# MCXC444 register map
Vendor: NXP Semiconductors; Series: MCX; File version: 1.6
CPU: CM0PLUS r0p0, little endian, no MPU, no FPU, VTOR, 2 interrupt priority bits
Registers are 32-bit, read-write, reset 0x0 unless marked. A register's access mark holds for its fields unless they carry their own. Offsets are from the block's base; [hi:lo] are bit positions; 'fields as' and 'values as' point back to an identical list.

## I2S0 — Inter-IC Sound / Synchronous Audio Interface
Base 0x4002F000; register names take the prefix I2S0_
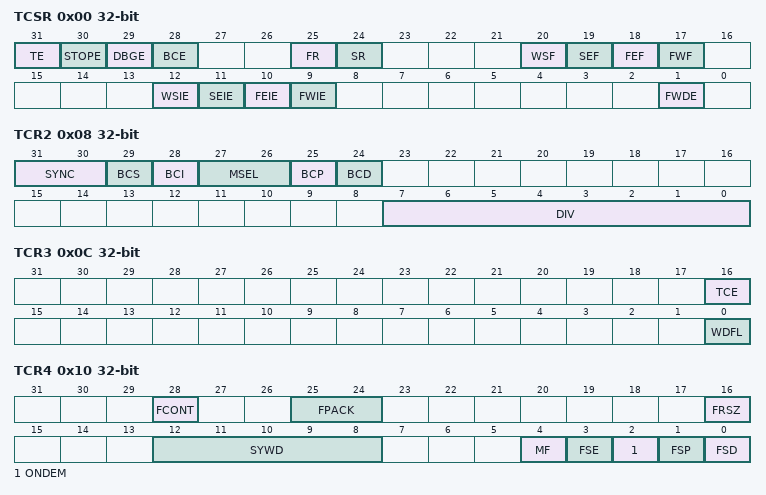
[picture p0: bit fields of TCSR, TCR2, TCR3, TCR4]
0x00 TCSR — SAI Transmit Control Register
  [31] TE — Transmitter Enable
    0=b0 (Transmitter is disabled.); 1=b1 (Transmitter is enabled, or transmitter has been disabled and has not yet reached end of frame.)
  [30] STOPE — Stop Enable
    0=b0 (Transmitter disabled in Stop mode.); 1=b1 (Transmitter enabled in Stop mode.)
  [29] DBGE — Debug Enable
    0=b0 (Transmitter is disabled in Debug mode, after completing the current frame.); 1=b1 (Transmitter is enabled in Debug mode.)
  [28] BCE — Bit Clock Enable
    0=b0 (Transmit bit clock is disabled.); 1=b1 (Transmit bit clock is enabled.)
  [25] FR — FIFO Reset
    0=b0 (No effect.); 1=b1 (FIFO reset.)
  [24] SR — Software Reset
    0=b0 (No effect.); 1=b1 (Software reset.)
  [20] WSF — Word Start Flag
    0=b0 (Start of word not detected.); 1=b1 (Start of word detected.)
  [19] SEF — Sync Error Flag
    0=b0 (Sync error not detected.); 1=b1 (Frame sync error detected.)
  [18] FEF — FIFO Error Flag
    0=b0 (Transmit underrun not detected.); 1=b1 (Transmit underrun detected.)
  [17] FWF ro — FIFO Warning Flag
    0=b0 (No enabled transmit FIFO is empty.); 1=b1 (Enabled transmit FIFO is empty.)
  [12] WSIE — Word Start Interrupt Enable
    0=b0 (Disables interrupt.); 1=b1 (Enables interrupt.)
  [11] SEIE — Sync Error Interrupt Enable
    0=b0 (Disables interrupt.); 1=b1 (Enables interrupt.)
  [10] FEIE — FIFO Error Interrupt Enable
    0=b0 (Disables the interrupt.); 1=b1 (Enables the interrupt.)
  [9] FWIE — FIFO Warning Interrupt Enable
    values as FEIE
  [1] FWDE — FIFO Warning DMA Enable
    0=b0 (Disables the DMA request.); 1=b1 (Enables the DMA request.)
0x08 TCR2 — SAI Transmit Configuration 2 Register
  [31:30] SYNC — Synchronous Mode
    0=b00 (Asynchronous mode.); 1=b01 (Synchronous with receiver.); 2=b10 (Synchronous with another SAI transmitter.); 3=b11 (Synchronous with another SAI receiver.)
  [29] BCS — Bit Clock Swap
    0=b0 (Use the normal bit clock source.); 1=b1 (Swap the bit clock source.)
  [28] BCI — Bit Clock Input
    0=b0 (No effect.); 1=b1 (Internal logic is clocked as if bit clock was externally generated.)
  [27:26] MSEL — MCLK Select
    0=b00 (Bus Clock selected.); 1=b01 (Master Clock (MCLK) 1 option selected.); 2=b10 (Master Clock (MCLK) 2 option selected.); 3=b11 (Master Clock (MCLK) 3 option selected.)
  [25] BCP — Bit Clock Polarity
    0=b0 (Bit clock is active high with drive outputs on rising edge and sample inputs on falling edge.); 1=b1 (Bit clock is active low with drive outputs on falling edge and sample inputs on rising edge.)
  [24] BCD — Bit Clock Direction
    0=b0 (Bit clock is generated externally in Slave mode.); 1=b1 (Bit clock is generated internally in Master mode.)
  [7:0] DIV — Bit Clock Divide
0x0C TCR3 — SAI Transmit Configuration 3 Register
  [16] TCE — Transmit Channel Enable
    0=b0 (Transmit data channel N is disabled.); 1=b1 (Transmit data channel N is enabled.)
  [0] WDFL — Word Flag Configuration
0x10 TCR4 — SAI Transmit Configuration 4 Register
  [28] FCONT — FIFO Continue on Error
    0=b0 (On FIFO error, the SAI will continue from the start of the next frame after the FIFO error flag has been cleared.); 1=b1 (On FIFO error, the SAI will continue from the same word that caused the FIFO error to set after the FIFO warning flag has been cleared.)
  [25:24] FPACK — FIFO Packing Mode
    0=b00 (FIFO packing is disabled); 2=b10 (8-bit FIFO packing is enabled); 3=b11 (16-bit FIFO packing is enabled)
  [16] FRSZ — Frame size
  [12:8] SYWD — Sync Width
  [4] MF — MSB First
    0=b0 (LSB is transmitted first.); 1=b1 (MSB is transmitted first.)
  [3] FSE — Frame Sync Early
    0=b0 (Frame sync asserts with the first bit of the frame.); 1=b1 (Frame sync asserts one bit before the first bit of the frame.)
  [2] ONDEM — On Demand Mode
    0=b0 (Internal frame sync is generated continuously.); 1=b1 (Internal frame sync is generated when the FIFO warning flag is clear.)
  [1] FSP — Frame Sync Polarity
    0=b0 (Frame sync is active high.); 1=b1 (Frame sync is active low.)
  [0] FSD — Frame Sync Direction
    0=b0 (Frame sync is generated externally in Slave mode.); 1=b1 (Frame sync is generated internally in Master mode.)
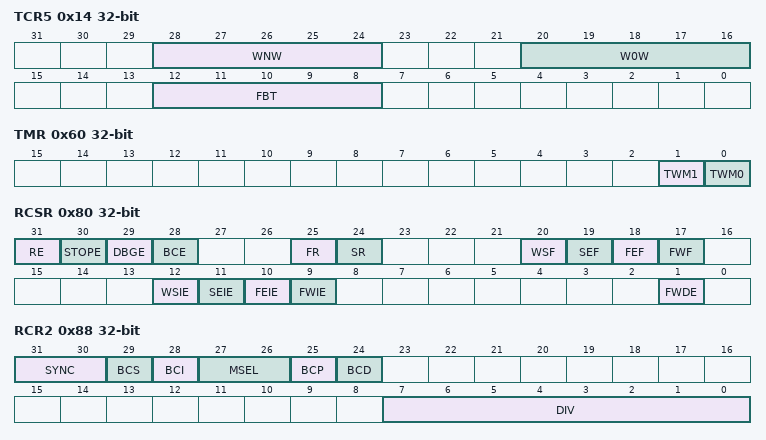
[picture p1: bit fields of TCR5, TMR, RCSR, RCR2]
0x14 TCR5 — SAI Transmit Configuration 5 Register
  [28:24] WNW — Word N Width
  [20:16] W0W — Word 0 Width
  [12:8] FBT — First Bit Shifted
0x20 TDR — SAI Transmit Data Register
  [31:0] TDR — Transmit Data Register
0x60 TMR — SAI Transmit Mask Register
  [1] TWM1 — Transmit Word Mask
    0=b00 (Word N is enabled.); 1=b01 (Word N is masked. The transmit data pins are tri-stated when masked.)
  [0] TWM0 — Transmit Word Mask
    values as TWM1
0x80 RCSR — SAI Receive Control Register
  [31] RE — Receiver Enable
    0=b0 (Receiver is disabled.); 1=b1 (Receiver is enabled, or receiver has been disabled and has not yet reached end of frame.)
  [30] STOPE — Stop Enable
    0=b0 (Receiver disabled in Stop mode.); 1=b1 (Receiver enabled in Stop mode.)
  [29] DBGE — Debug Enable
    0=b0 (Receiver is disabled in Debug mode, after completing the current frame.); 1=b1 (Receiver is enabled in Debug mode.)
  [28] BCE — Bit Clock Enable
    0=b0 (Receive bit clock is disabled.); 1=b1 (Receive bit clock is enabled.)
  [25] FR — FIFO Reset
    0=b0 (No effect.); 1=b1 (FIFO reset.)
  [24] SR — Software Reset
    0=b0 (No effect.); 1=b1 (Software reset.)
  [20] WSF — Word Start Flag
    values as TCSR.WSF
  [19] SEF — Sync Error Flag
    values as TCSR.SEF
  [18] FEF — FIFO Error Flag
    0=b0 (Receive overflow not detected.); 1=b1 (Receive overflow detected.)
  [17] FWF ro — FIFO Warning Flag
    0=b0 (No enabled receive FIFO is full.); 1=b1 (Enabled receive FIFO is full.)
  [12] WSIE — Word Start Interrupt Enable
    0=b0 (Disables interrupt.); 1=b1 (Enables interrupt.)
  [11] SEIE — Sync Error Interrupt Enable
    0=b0 (Disables interrupt.); 1=b1 (Enables interrupt.)
  [10] FEIE — FIFO Error Interrupt Enable
    values as TCSR.FEIE
  [9] FWIE — FIFO Warning Interrupt Enable
    values as TCSR.FEIE
  [1] FWDE — FIFO Warning DMA Enable
    values as TCSR.FWDE
0x88 RCR2 — SAI Receive Configuration 2 Register
  [31:30] SYNC — Synchronous Mode
    0=b00 (Asynchronous mode.); 1=b01 (Synchronous with transmitter.); 2=b10 (Synchronous with another SAI receiver.); 3=b11 (Synchronous with another SAI transmitter.)
  [29] BCS — Bit Clock Swap
    values as TCR2.BCS
  [28] BCI — Bit Clock Input
    values as TCR2.BCI
  [27:26] MSEL — MCLK Select
    values as TCR2.MSEL
  [25] BCP — Bit Clock Polarity
    0=b0 (Bit Clock is active high with drive outputs on rising edge and sample inputs on falling edge.); 1=b1 (Bit Clock is active low with drive outputs on falling edge and sample inputs on rising edge.)
  [24] BCD — Bit Clock Direction
    values as TCR2.BCD
  [7:0] DIV — Bit Clock Divide
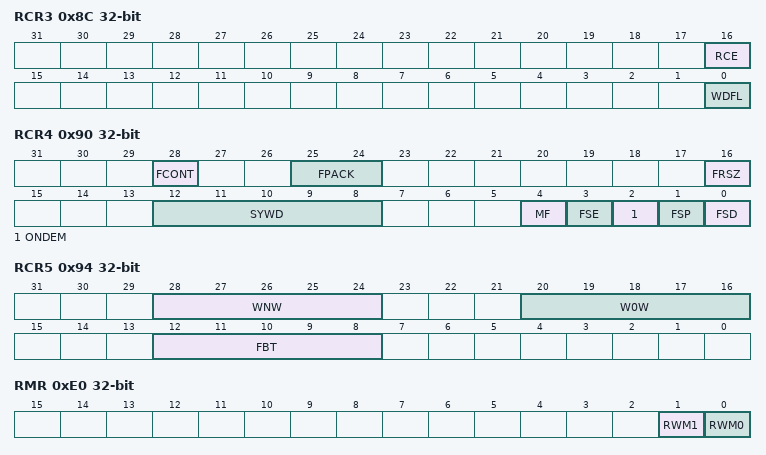
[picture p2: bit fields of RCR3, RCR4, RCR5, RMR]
0x8C RCR3 — SAI Receive Configuration 3 Register
  [16] RCE — Receive Channel Enable
    0=b0 (Receive data channel N is disabled.); 1=b1 (Receive data channel N is enabled.)
  [0] WDFL — Word Flag Configuration
0x90 RCR4 — SAI Receive Configuration 4 Register
  [28] FCONT — FIFO Continue on Error
    values as TCR4.FCONT
  [25:24] FPACK — FIFO Packing Mode
    values as TCR4.FPACK
  [16] FRSZ — Frame Size
  [12:8] SYWD — Sync Width
  [4] MF — MSB First
    0=b0 (LSB is received first.); 1=b1 (MSB is received first.)
  [3] FSE — Frame Sync Early
    values as TCR4.FSE
  [2] ONDEM — On Demand Mode
    values as TCR4.ONDEM
  [1] FSP — Frame Sync Polarity
    values as TCR4.FSP
  [0] FSD — Frame Sync Direction
    0=b0 (Frame Sync is generated externally in Slave mode.); 1=b1 (Frame Sync is generated internally in Master mode.)
0x94 RCR5 — SAI Receive Configuration 5 Register
  fields as TCR5
0xA0 RDR ro — SAI Receive Data Register
  [31:0] RDR — Receive Data Register
0xE0 RMR — SAI Receive Mask Register
  [1] RWM1 — Receive Word Mask
    0=b00 (Word N is enabled.); 1=b01 (Word N is masked.)
  [0] RWM0 — Receive Word Mask
    0=b00 (Word N is enabled.); 1=b01 (Word N is masked.)
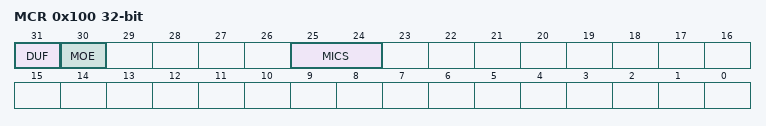
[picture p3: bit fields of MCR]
0x100 MCR — SAI MCLK Control Register
  [31] DUF ro — Divider Update Flag
    0=b0 (MCLK divider ratio is not being updated currently.); 1=b1 (MCLK divider ratio is updating on-the-fly. Further updates to the MCLK divider ratio are blocked while this flag remains set.)
  [30] MOE — MCLK Output Enable
    0=b0 (MCLK signal pin is configured as an input that bypasses the MCLK divider.); 1=b1 (MCLK signal pin is configured as an output from the MCLK divider and the MCLK divider is enabled.)
  [25:24] MICS — MCLK Input Clock Select
    0=b00 (MCLK divider input clock 0 selected.); 1=b01 (MCLK divider input clock 1 selected.); 2=b10 (MCLK divider input clock 2 selected.); 3=b11 (MCLK divider input clock 3 selected.)
